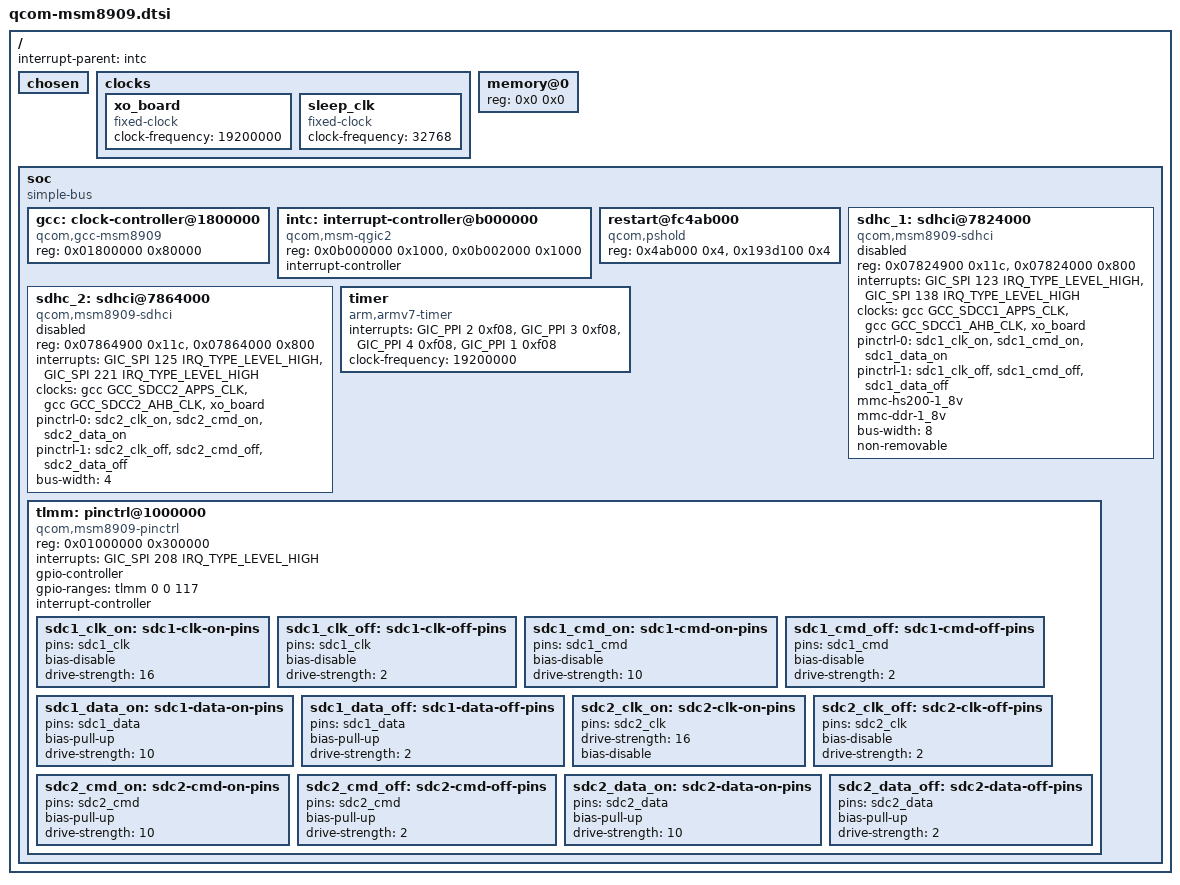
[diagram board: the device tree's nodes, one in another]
// SPDX-License-Identifier: BSD-3-Clause
/*
 * Copyright (c) 2022, The Linux Foundation. All rights reserved.
 */

/dts-v1/;

#include <dt-bindings/clock/qcom,gcc-msm8909.h>
#include <dt-bindings/gpio/gpio.h>
#include <dt-bindings/interrupt-controller/arm-gic.h>
#include <dt-bindings/reset/qcom,gcc-msm8909.h>

/ {
	#address-cells = <1>;
	#size-cells = <1>;
	interrupt-parent = <&intc>;
	
	chosen { };

	clocks {
		xo_board: xo_board {
			compatible = "fixed-clock";
			#clock-cells = <0>;
			clock-frequency = <19200000>;
		};

		sleep_clk: sleep_clk {
			compatible = "fixed-clock";
			#clock-cells = <0>;
			clock-frequency = <32768>;
		};
	};

	memory@0 {
		device_type = "memory";
		reg = <0x0 0x0>;
	};

	soc: soc {
		compatible = "simple-bus";
		#address-cells = <1>;
		#size-cells = <1>;
		ranges;

		gcc: clock-controller@1800000 {
			compatible = "qcom,gcc-msm8909";
			#clock-cells = <1>;
			#reset-cells = <1>;
			#power-domain-cells = <1>;
			reg = <0x01800000 0x80000>;
		};

		intc: interrupt-controller@b000000 {
			compatible = "qcom,msm-qgic2";
			reg = <0x0b000000 0x1000>,
			      <0x0b002000 0x1000>;
			interrupt-controller;
			#interrupt-cells = <3>;
		};
		
		restart@fc4ab000 {
			compatible = "qcom,pshold";
			reg = <0x4ab000 0x4>,
			      <0x193d100 0x4>;
		};
		
		sdhc_1: sdhci@7824000 {
			compatible = "qcom,msm8909-sdhci", "qcom,sdhci-msm-v4";
			reg = <0x07824900 0x11c>, <0x07824000 0x800>;
			reg-names = "hc_mem", "core_mem";

			interrupts = <GIC_SPI 123 IRQ_TYPE_LEVEL_HIGH>,
				   		 <GIC_SPI 138 IRQ_TYPE_LEVEL_HIGH>;
			interrupt-names = "hc_irq", "pwr_irq";
			clocks = <&gcc GCC_SDCC1_APPS_CLK>,
					 <&gcc GCC_SDCC1_AHB_CLK>,
				 	 <&xo_board>;
			clock-names = "core", "iface", "xo";

			pinctrl-names = "default", "sleep";
			pinctrl-0 = <&sdc1_clk_on &sdc1_cmd_on &sdc1_data_on>;
			pinctrl-1 = <&sdc1_clk_off &sdc1_cmd_off &sdc1_data_off>;

			mmc-hs200-1_8v;
			mmc-ddr-1_8v;
			bus-width = <8>;
			non-removable;
			status = "disabled";
		};

		sdhc_2: sdhci@7864000 {
			compatible = "qcom,msm8909-sdhci", "qcom,sdhci-msm-v4";
			reg = <0x07864900 0x11c>, <0x07864000 0x800>;
			reg-names = "hc_mem", "core_mem";

			interrupts = <GIC_SPI 125 IRQ_TYPE_LEVEL_HIGH>,
				    	 <GIC_SPI 221 IRQ_TYPE_LEVEL_HIGH>;
			interrupt-names = "hc_irq", "pwr_irq";
			clocks = <&gcc GCC_SDCC2_APPS_CLK>,
					 <&gcc GCC_SDCC2_AHB_CLK>,
					 <&xo_board>;
			clock-names = "core", "iface", "xo";
			
			pinctrl-names = "default", "sleep";
			pinctrl-0 = <&sdc2_clk_on &sdc2_cmd_on &sdc2_data_on>;
			pinctrl-1 = <&sdc2_clk_off &sdc2_cmd_off &sdc2_data_off>;

			bus-width = <4>;
			status = "disabled";
		};

		timer {
			compatible = "arm,armv7-timer";
			interrupts = <GIC_PPI 2 0xf08>,
				    	 <GIC_PPI 3 0xf08>,
				     	 <GIC_PPI 4 0xf08>,
			     	 	 <GIC_PPI 1 0xf08>;
			clock-frequency = <19200000>;
		};

		tlmm: pinctrl@1000000 {
			compatible = "qcom,msm8909-pinctrl";
			reg = <0x01000000 0x300000>;
			interrupts = <GIC_SPI 208 IRQ_TYPE_LEVEL_HIGH>;
			gpio-controller;
			#gpio-cells = <2>;
			gpio-ranges = <&tlmm 0 0 117>;
			interrupt-controller;
			#interrupt-cells = <2>;
			
			sdc1_clk_on: sdc1-clk-on-pins {
				pins = "sdc1_clk";
				bias-disable;
				drive-strength = <16>;
			};

			sdc1_clk_off: sdc1-clk-off-pins {
				pins = "sdc1_clk";
				bias-disable;
				drive-strength = <2>;
			};

			sdc1_cmd_on: sdc1-cmd-on-pins {
				pins = "sdc1_cmd";
				bias-disable;
				drive-strength = <10>;
			};

			sdc1_cmd_off: sdc1-cmd-off-pins {
				pins = "sdc1_cmd";
				bias-disable;
				drive-strength = <2>;
			};

			sdc1_data_on: sdc1-data-on-pins {
				pins = "sdc1_data";
				bias-pull-up;
				drive-strength = <10>;
			};

			sdc1_data_off: sdc1-data-off-pins {
				pins = "sdc1_data";
				bias-pull-up;
				drive-strength = <2>;
			};

			sdc2_clk_on: sdc2-clk-on-pins {
				pins = "sdc2_clk";
				drive-strength = <16>;
				bias-disable;
			};

			sdc2_clk_off: sdc2-clk-off-pins {
				pins = "sdc2_clk";
				bias-disable;
				drive-strength = <2>;
			};

			sdc2_cmd_on: sdc2-cmd-on-pins {
				pins = "sdc2_cmd";
				bias-pull-up;
				drive-strength = <10>;
			};

			sdc2_cmd_off: sdc2-cmd-off-pins {
				pins = "sdc2_cmd";
				bias-pull-up;
				drive-strength = <2>;
			};

			sdc2_data_on: sdc2-data-on-pins {
				pins = "sdc2_data";
				bias-pull-up;
				drive-strength = <10>;
			};

			sdc2_data_off: sdc2-data-off-pins {
				pins = "sdc2_data";
				bias-pull-up;
				drive-strength = <2>;
			};
		};
	};
};
